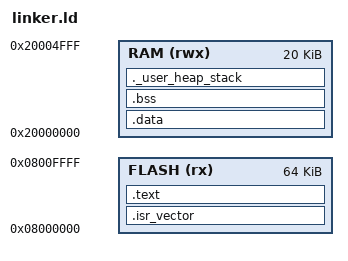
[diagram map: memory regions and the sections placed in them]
ENTRY(Reset_Handler)

MEMORY
{
    FLASH (rx) : ORIGIN = 0x08000000, LENGTH = 64K
    RAM   (rwx): ORIGIN = 0x20000000, LENGTH = 20K
}

_estack = ORIGIN(RAM) + LENGTH(RAM);

SECTIONS
{
    .isr_vector :
    {
        KEEP(*(.isr_vector))
    } > FLASH

    .text :
    {
        *(.text*)
        *(.rodata*)
        *(.glue_7*)
        *(.glue_7t*)
        *(.eh_frame*)

        KEEP(*(.init))
        KEEP(*(.fini))
    } > FLASH

    _sidata = LOADADDR(.data);

    .data : AT (ADDR(.text) + SIZEOF(.text))
    {
        _sdata = .;
        *(.data*)
        *(.ramfunc*)
        _edata = .;
    } > RAM

    .bss :
    {
        _sbss = .;
        *(.bss*)
        *(COMMON)
        _ebss = .;
    } > RAM

    ._user_heap_stack :
    {
        . = ALIGN(8);
        *(.heap*)
        *(.stack*)
        . = ALIGN(8);
    } > RAM
}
